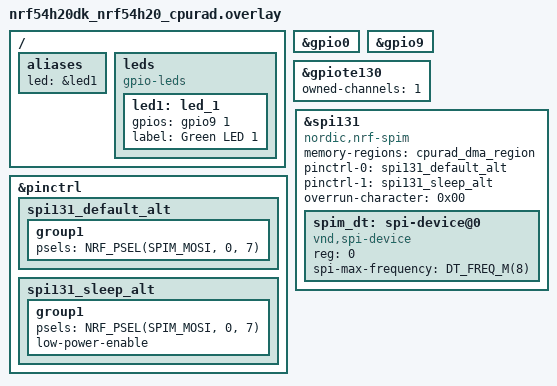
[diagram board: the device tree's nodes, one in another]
/*
 * Copyright (c) 2026 Nordic Semiconductor
 *
 * SPDX-License-Identifier: LicenseRef-Nordic-5-Clause
 */

/ {
	aliases {
		led = &led1;
	};

	leds {
		compatible = "gpio-leds";

		led1: led_1 {
			gpios = <&gpio9 1 GPIO_ACTIVE_HIGH>;
			label = "Green LED 1";
		};
	};
};

&gpio0 {
	status = "okay";
};

&gpio9 {
	status = "okay";
};

&gpiote130 {
	status = "okay";
	owned-channels = <1>;
};

&pinctrl {
	spi131_default_alt: spi131_default_alt {
		group1 {
			psels = <NRF_PSEL(SPIM_MOSI, 0, 7)>;
		};
	};

	spi131_sleep_alt: spi131_sleep_alt {
		group1 {
			psels = <NRF_PSEL(SPIM_MOSI, 0, 7)>;
			low-power-enable;
		};
	};
};

&spi131 {
	compatible = "nordic,nrf-spim";
	status = "okay";
	memory-regions = <&cpurad_dma_region>;
	pinctrl-0 = <&spi131_default_alt>;
	pinctrl-1 = <&spi131_sleep_alt>;
	pinctrl-names = "default", "sleep";
	overrun-character = <0x00>;

	spim_dt: spi-device@0 {
		compatible = "vnd,spi-device";
		reg = <0>;
		spi-max-frequency = <DT_FREQ_M(8)>;
	};
};
